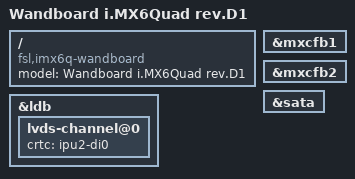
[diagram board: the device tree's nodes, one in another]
/*
 * Copyright 2013-2017 Freescale Semiconductor, Inc.
 * Copyright 2017 Wandboard, Org.
 *
 * Author: Fabio Estevam <fabio.estevam@freescale.com>
 *         Richard Hu <richard.hu@technexion.com>
 *
 * This program is free software; you can redistribute it and/or modify
 * it under the terms of the GNU General Public License version 2 as
 * published by the Free Software Foundation.
 *
 */

/dts-v1/;

#include <dt-bindings/interrupt-controller/irq.h>
#include "imx6q.dtsi"
#include "imx6qdl-wandboard-revd1.dtsi"

/ {
	model = "Wandboard i.MX6Quad rev.D1";
	compatible = "fsl,imx6q-wandboard", "fsl,imx6q";
};

&ldb {
	lvds-channel@0 {
		crtc = "ipu2-di0";
	};
};

&mxcfb1 {
	status = "okay";
};

&mxcfb2 {
	status = "okay";
};

#if 0
&mxcfb3 {
	status = "okay";
};

&mxcfb4 {
	status = "okay";
};
#endif

&sata {
	status = "okay";
};
